# S32K324_M7 register map
Vendor: NXP Semiconductors; File version: 1.1
CPU: CM7 r0p1, little endian, MPU, FPU, VTOR, 4 interrupt priority bits
Registers are 32-bit, read-write, reset 0x0 unless marked. A register's access mark holds for its fields unless they carry their own. Offsets are from the block's base; [hi:lo] are bit positions; {n}, {i} and the like mark numbered series; 'fields as' and 'values as' point back to an identical list.

## EMIOS_0 — eMIOS
Base 0x40088000
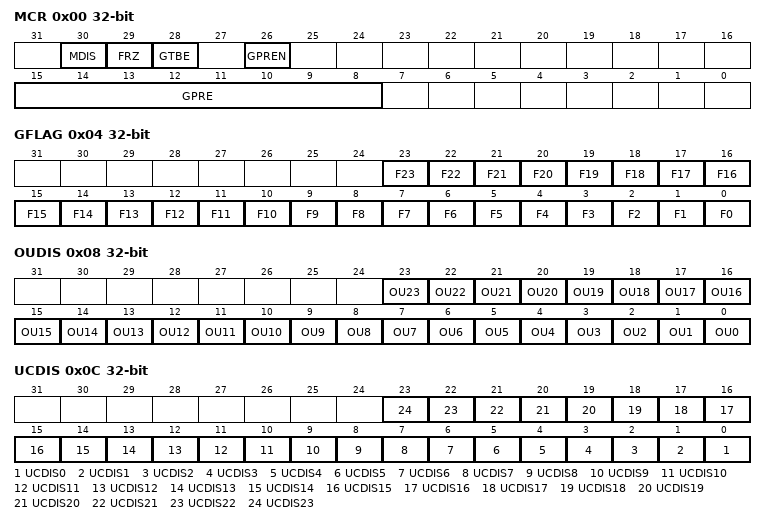
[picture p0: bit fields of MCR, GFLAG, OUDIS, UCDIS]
0x00 MCR — Module Configuration
  [30] MDIS — Module Disable
    0=ENABLED; 1=DISABLED
  [29] FRZ — Freeze
    0=EXIT_FREEZE (Exit Freeze state); 1=ENTER_FREEZE (Enter Freeze state)
  [28] GTBE — Global Timebase Enable
    0=DEASSERTED (Deassert GTBE_OUT); 1=ASSERTED (Assert GTBE_OUT)
  [26] GPREN — Global Prescaler Enable
    0=disable; 1=enable
  [15:8] GPRE — Global Prescaler
0x04 GFLAG ro — Global Flag
  [n] F{n} (n=0..23) — Mirror of UC {n} FLAG
0x08 OUDIS — Output Update Disable
  [all] fields
    0=ENABLED; 1=DISABLED
  [n] OU{n} (n=0..23) — Channel {n} Output Update Disable
0x0C UCDIS — Disable Channel
  [all] fields
    0=ENABLED; 1=DISABLED
  [n] UCDIS{n} (n=0..23) — Disable UC {n}
{0x20+0x20*i} A{i} (i=0..23) — UC A {i}
  [15:0] A
{0x24+0x20*i} B{i} (i=0..23) — UC B {i}
  [15:0] B
{0x28+0x20*i} CNT{i} (i=0..8) — UC Counter {i}
  [15:0] C — Internal Counter Value
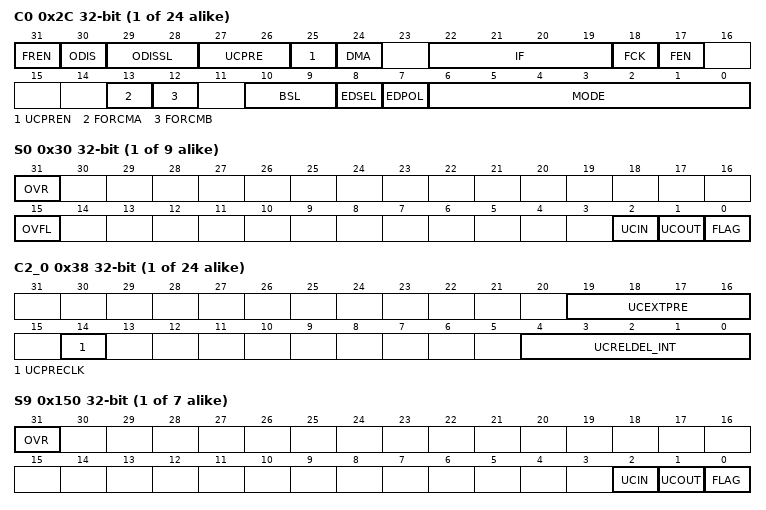
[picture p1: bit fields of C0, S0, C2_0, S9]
{0x2C+0x20*i} C{i} (i=0..23) — UC Control {i}
  [31] FREN — Freeze Enable
    0=FREEZE_NO (Disable); 1=FREEZE_YES (Enable)
  [30] ODIS — Output Disable
    0=ENABLE (Enables output pin (the output pin operates normally)); 1=DISABLE (Disables output pin)
  [29:28] ODISSL — Output Disable Select
    {v}=INPUT_{v} ({v}) (v=0..3)
  [27:26] UCPRE — Prescaler
    {v}=DIVIDE_{v+1} ({v+1}) (v=0..3)
  [25] UCPREN — Prescaler Enable
    0=DISABLED (Disable (no clock)); 1=ENABLED
  [24] DMA — Direct Memory Access
    0=INTERRUPT (Interrupt request); 1=DMA (DMA request)
  [22:19] IF — Input Filter
    0=BYPASSED (Bypassed; the input signal is synchronized before arriving at the digital filter); 1=PERIODS_2 (2 cycles); 2=PERIODS_4 (4 cycles); 4=PERIODS_8 (8 cycles); 8=PERIODS_16 (16 cycles)
  [18] FCK — Filter Clock Select
    0=PRESCALED (Prescaled clock); 1=MODULE (eMIOS module clock)
  [17] FEN — Flag Enable
    0=DISABLE; 1=ENABLE
  [13] FORCMA wo — Force Match A
    0=NO_EFFECT; 1=FORCE_MATCH (Force a match at comparator A)
  [12] FORCMB wo — Force Match B
    0=NO_EFFECT; 1=FORCE_MATCH (Force a match at comparator B)
  [10:9] BSL — Bus Select
  [8] EDSEL — Edge Selection
  [7] EDPOL — Edge Polarity
  [6:0] MODE — Mode Selection
{0x30+0x20*i} S{i} (reset mask 0xFFFFFFFB) (i=0..8) — UC Status {i}
  [31] OVR write-1-clears — Overrun
    on read: 0=OVR_NO (No overrun); 1=OVR_YES (Overrun) | on write: 0=OVR_NO (No overrun)
  [15] OVFL write-1-clears — Overflow
    on read: 0=OVFL_NO (No overflow); 1=OVFL_YES (Overflow) | on write: 0=OVFL_NO (No overflow)
  [2] UCIN ro — UC Input Pin
    0=NEGATED; 1=ASSERTED
  [1] UCOUT ro — UC Output Pin
    0=NEGATED; 1=ASSERTED
  [0] FLAG write-1-clears
    on read: 0=EVENT_NO (No event); 1=EVENT_YES (Event has occurred) | on write: 0=EVENT_NO (No event)
{0x34+0x20*i} ALTA{i} (i=0..23) — Alternate Address {i}
  [15:0] ALTA — Alternate Address
{0x38+0x20*i} C2_{i} (i=0..23) — UC Control 2 {i}
  [19:16] UCEXTPRE — Extended Prescaler
  [14] UCPRECLK — Prescaler Clock Source
    0=Prescaled clock; 1=module (eMIOS module clock)
  [4:0] UCRELDEL_INT — Reload Signal Output Delay Interval
{0x30+0x20*i} S{i} (reset mask 0xFFFFFFFB) (i=9..15) — UC Status {i}
  [31] OVR write-1-clears — Overrun
    values as S0.OVR
  [2] UCIN ro — UC Input Pin
    0=NEGATED; 1=ASSERTED
  [1] UCOUT ro — UC Output Pin
    0=NEGATED; 1=ASSERTED
  [0] FLAG write-1-clears
    values as S0.FLAG
0x228 CNT16 — UC Counter 16
  [15:0] C — Internal Counter Value
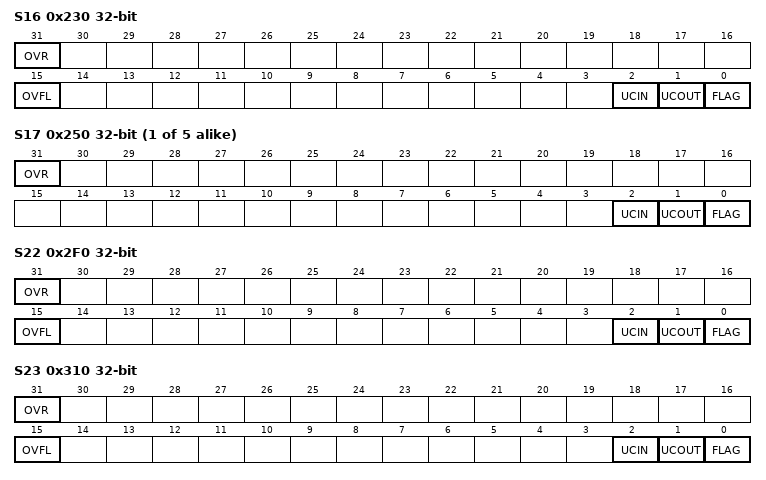
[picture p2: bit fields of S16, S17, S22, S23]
0x230 S16 (reset mask 0xFFFFFFFB) — UC Status 16
  fields as S0
{0x30+0x20*i} S{i} (reset mask 0xFFFFFFFB) (i=17..21) — UC Status {i}
  fields as S9
0x2E8 CNT22 — UC Counter 22
  [15:0] C — Internal Counter Value
0x2F0 S22 (reset mask 0xFFFFFFFB) — UC Status 22
  fields as S0
0x308 CNT23 — UC Counter 23
  [15:0] C — Internal Counter Value
0x310 S23 (reset mask 0xFFFFFFFB) — UC Status 23
  fields as S0

## EMIOS_1 — eMIOS
Base 0x4008C000
Same registers: EMIOS_2 0x40090000
Registers as EMIOS_0, without CNT{n} (n=1..7); these are added or differ:
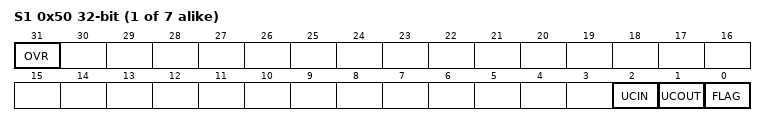
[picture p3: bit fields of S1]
{0x30+0x20*i} S{i} (reset mask 0xFFFFFFFB) (i=1..7) — UC Status {i}
  fields as EMIOS_0.S9
